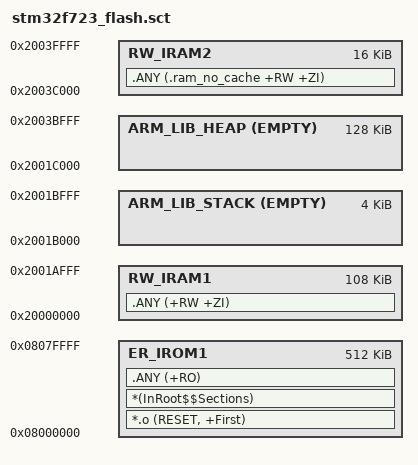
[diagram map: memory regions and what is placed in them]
;********************************************************************
;* STM32F723 linker scatter file (running code from internal FLASH) *
;********************************************************************

LR_IROM1 0x08000000 0x80000
{
   ER_IROM1 0x08000000 0x80000
   {
      *.o (RESET, +First)
      *(InRoot$$Sections)
      .ANY (+RO)
   }
   
   RW_IRAM1 0x20000000 0x1B000
   { 
      .ANY (+RW +ZI)
   }
   
   ARM_LIB_STACK 0x2001C000 EMPTY -0x1000
   {
   }
   
   ARM_LIB_HEAP 0x2001C000 EMPTY 0x20000
   {
   }
   
   RW_IRAM2 0x2003C000 0x4000
   {
      .ANY (.ram_no_cache +RW +ZI)
   }
}
